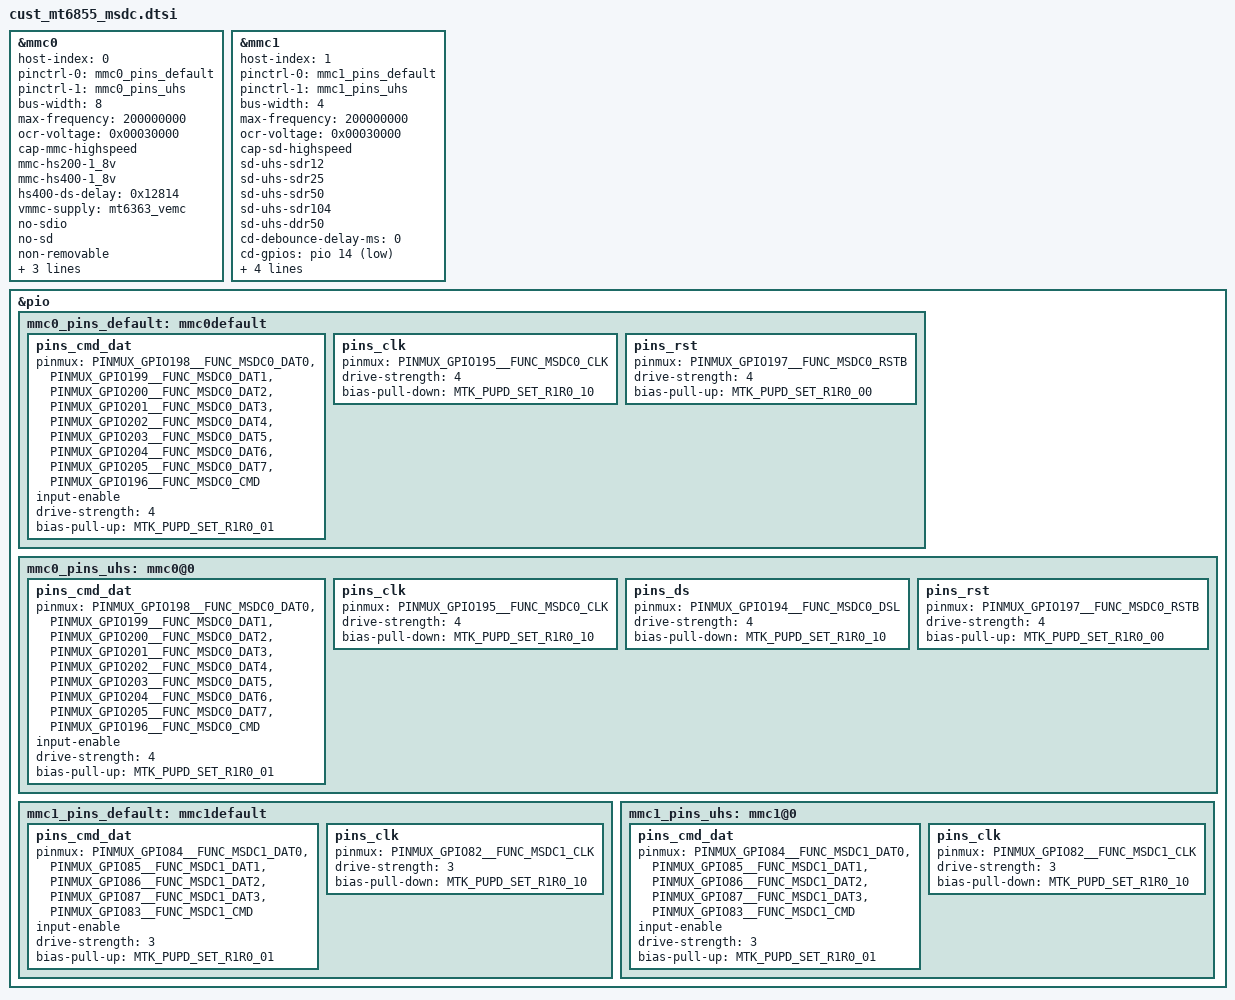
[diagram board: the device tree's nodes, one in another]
// SPDX-License-Identifier: GPL-2.0
/*
 * Copyright (c) 2020 MediaTek Inc.
 */
/********************************************
 * MT6855 MSDC DTSI File
 ********************************************/
#include <dt-bindings/gpio/gpio.h>
&mmc0 {
	host-index = <0>;
	status = "okay";
	pinctrl-names = "default", "state_uhs";
	pinctrl-0 = <&mmc0_pins_default>;
	pinctrl-1 = <&mmc0_pins_uhs>;
	bus-width = <8>;
	max-frequency = <200000000>;
	ocr-voltage = <0x00030000>;
	cap-mmc-highspeed;
	mmc-hs200-1_8v;
	mmc-hs400-1_8v;
	hs400-ds-delay = <0x12814>;
	vmmc-supply = <&mt6363_vemc>;
	no-sdio;
	no-sd;
	non-removable;
	supports-cqe;
	dvfsrc-vcore-supply = <&dvfsrc_vcore>;
	req-vcore = <650000>;
};

&mmc1 {
	host-index = <1>;
	status = "okay";
	pinctrl-names = "default", "state_uhs";
	pinctrl-0 = <&mmc1_pins_default>;
	pinctrl-1 = <&mmc1_pins_uhs>;
	bus-width = <4>;
	max-frequency = <200000000>;
	ocr-voltage = <0x00030000>;
	cap-sd-highspeed;
	sd-uhs-sdr12;
	sd-uhs-sdr25;
	sd-uhs-sdr50;
	sd-uhs-sdr104;
	sd-uhs-ddr50;
	cd-debounce-delay-ms = <0>;
	cd-gpios = <&pio 14 GPIO_ACTIVE_LOW>;
	vmmc-supply = <&mt6369_vmch_eint_high>;
	vqmmc-supply = <&mt6369_vmc>;
	no-mmc;
	no-sdio;
};

&pio {
	mmc0_pins_default: mmc0default {
		pins_cmd_dat {
			pinmux = <PINMUX_GPIO198__FUNC_MSDC0_DAT0>,
				<PINMUX_GPIO199__FUNC_MSDC0_DAT1>,
				<PINMUX_GPIO200__FUNC_MSDC0_DAT2>,
				<PINMUX_GPIO201__FUNC_MSDC0_DAT3>,
				<PINMUX_GPIO202__FUNC_MSDC0_DAT4>,
				<PINMUX_GPIO203__FUNC_MSDC0_DAT5>,
				<PINMUX_GPIO204__FUNC_MSDC0_DAT6>,
				<PINMUX_GPIO205__FUNC_MSDC0_DAT7>,
				<PINMUX_GPIO196__FUNC_MSDC0_CMD>;
			input-enable;
			drive-strength = <4>;
			bias-pull-up = <MTK_PUPD_SET_R1R0_01>;
		};
		pins_clk {
			pinmux = <PINMUX_GPIO195__FUNC_MSDC0_CLK>;
			drive-strength = <4>;
			bias-pull-down = <MTK_PUPD_SET_R1R0_10>;
		};
		pins_rst {
			pinmux = <PINMUX_GPIO197__FUNC_MSDC0_RSTB>;
			drive-strength = <4>;
			bias-pull-up = <MTK_PUPD_SET_R1R0_00>;
		};
	};
	mmc0_pins_uhs: mmc0@0{
		pins_cmd_dat {
			pinmux = <PINMUX_GPIO198__FUNC_MSDC0_DAT0>,
				<PINMUX_GPIO199__FUNC_MSDC0_DAT1>,
				<PINMUX_GPIO200__FUNC_MSDC0_DAT2>,
				<PINMUX_GPIO201__FUNC_MSDC0_DAT3>,
				<PINMUX_GPIO202__FUNC_MSDC0_DAT4>,
				<PINMUX_GPIO203__FUNC_MSDC0_DAT5>,
				<PINMUX_GPIO204__FUNC_MSDC0_DAT6>,
				<PINMUX_GPIO205__FUNC_MSDC0_DAT7>,
				<PINMUX_GPIO196__FUNC_MSDC0_CMD>;
			input-enable;
			drive-strength = <4>;
			bias-pull-up = <MTK_PUPD_SET_R1R0_01>;
		};
		pins_clk {
			pinmux = <PINMUX_GPIO195__FUNC_MSDC0_CLK>;
			drive-strength = <4>;
			bias-pull-down = <MTK_PUPD_SET_R1R0_10>;
		};
		pins_ds {
			pinmux = <PINMUX_GPIO194__FUNC_MSDC0_DSL>;
			drive-strength = <4>;
			bias-pull-down = <MTK_PUPD_SET_R1R0_10>;
		};
		pins_rst {
			pinmux = <PINMUX_GPIO197__FUNC_MSDC0_RSTB>;
			drive-strength = <4>;
			bias-pull-up = <MTK_PUPD_SET_R1R0_00>;
		};
	};
	mmc1_pins_default: mmc1default {
		pins_cmd_dat {
			pinmux = <PINMUX_GPIO84__FUNC_MSDC1_DAT0>,
				<PINMUX_GPIO85__FUNC_MSDC1_DAT1>,
				<PINMUX_GPIO86__FUNC_MSDC1_DAT2>,
				<PINMUX_GPIO87__FUNC_MSDC1_DAT3>,
				<PINMUX_GPIO83__FUNC_MSDC1_CMD>;
			input-enable;
			drive-strength = <3>;
			bias-pull-up = <MTK_PUPD_SET_R1R0_01>;
		};

		pins_clk {
			pinmux = <PINMUX_GPIO82__FUNC_MSDC1_CLK>;
			drive-strength = <3>;
			bias-pull-down = <MTK_PUPD_SET_R1R0_10>;
		};
	};
	mmc1_pins_uhs: mmc1@0{
		pins_cmd_dat {
			pinmux = <PINMUX_GPIO84__FUNC_MSDC1_DAT0>,
				<PINMUX_GPIO85__FUNC_MSDC1_DAT1>,
				<PINMUX_GPIO86__FUNC_MSDC1_DAT2>,
				<PINMUX_GPIO87__FUNC_MSDC1_DAT3>,
				<PINMUX_GPIO83__FUNC_MSDC1_CMD>;
			input-enable;
			drive-strength = <3>;
			bias-pull-up = <MTK_PUPD_SET_R1R0_01>;
		};

		pins_clk {
			pinmux = <PINMUX_GPIO82__FUNC_MSDC1_CLK>;
			drive-strength = <3>;
			bias-pull-down = <MTK_PUPD_SET_R1R0_10>;
		};
	};
};
